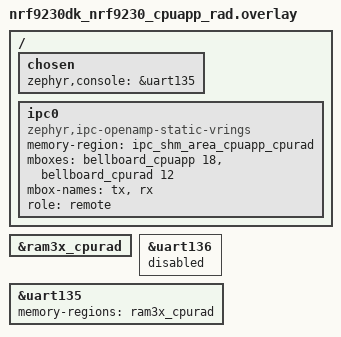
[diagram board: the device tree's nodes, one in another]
/*
 * Copyright (c) 2023 Nordic Semiconductor ASA
 *
 * SPDX-License-Identifier: Apache-2.0
 */

#include <common/nordic_nrf_next/nrfx_ram3x_dma.dtsi>

/{
	chosen {
		zephyr,console = &uart135;
	};

	ipc0: ipc0 {
		compatible = "zephyr,ipc-openamp-static-vrings";
		memory-region = <&ipc_shm_area_cpuapp_cpurad>;
		mboxes = <&bellboard_cpuapp 18>,
			 <&bellboard_cpurad 12>;
		mbox-names = "tx", "rx";
		role = "remote";
		status = "okay";
	};
};

&ram3x_cpurad {
	status = "okay";
};

&uart136 {
	status = "disabled";
};

&uart135 {
	status = "okay";
	memory-regions = <&ram3x_cpurad>;
};
